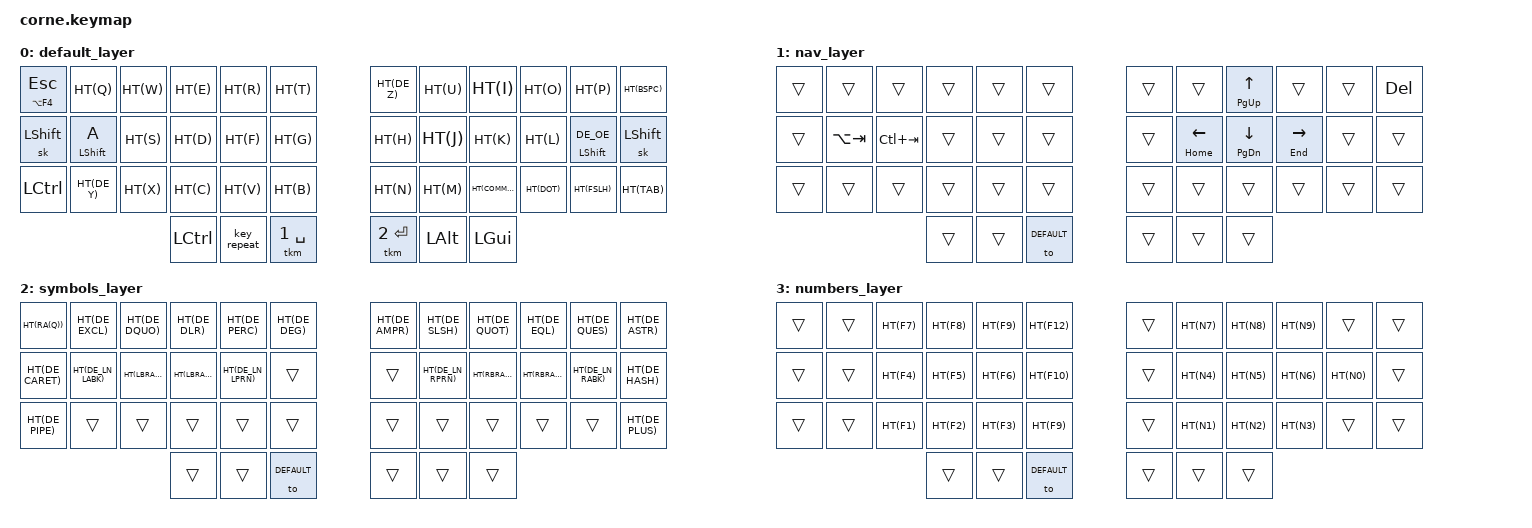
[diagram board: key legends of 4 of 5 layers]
/*
 * Copyright (c) 2020 The ZMK Contributors
 *
 * SPDX-License-Identifier: MIT
 */

#include <behaviors.dtsi>
#include <dt-bindings/zmk/keys.h>
#include <dt-bindings/zmk/bt.h>
#include <dt-bindings/zmk/outputs.h>
#include <dt-bindings/zmk/ext_power.h>
#include <dt-bindings/led/led.h>
#include <dt-bindings/zmk/backlight.h>
#include <dt-bindings/zmk/rgb.h>
#include <dt-bindings/zmk/reset.h>

#include "helper.h"
#include "symbols.h"
#include "keypos_42keys.h"

&led_strip {
    chain-length = <27>;
};

ZMK_BEHAVIOR(hrm, hold_tap,
    flavor = "balanced";
    tapping-term-ms = <280>;
    quick-tap-ms = <175>;
    bindings = <&kp>, <&kp>;
)

ZMK_BEHAVIOR(tkm, hold_tap,
    flavor = "balanced";
    tapping-term-ms = <280>;
    quick-tap-ms = <175>;
    bindings = <&mo>, <&kp>;
)

// Custom Combos
#undef COMBO_TERM
#define COMBO_TERM 50

#define DEFAULT 0
#define NAV 1
#define SYM 2
#define NUM 3
#define SYS 4

#define ______ &trans
#define HT(key) &hrm LC(key) key

ZMK_COMBO(sz,  &kp DE_SZ, LM3 RT0, ALL)
ZMK_COMBO(ue, &kp DE_UE, RT1 LT2, ALL)
ZMK_COMBO(ae, &kp DE_AE, LM4 LT2, ALL)
ZMK_COMBO(nav_layer, &to NAV, LM1 RM1, ALL)
ZMK_COMBO(sym_layer, &to SYM, LM2 RM2, ALL)
ZMK_COMBO(num_layer, &to NUM, LM3 RM3, ALL)
ZMK_COMBO(sys_layer_right, &mo 4, RH1 RH2, ALL)
ZMK_COMBO(sys_layer_left, &mo 4, LH1 LH2, ALL)

ZMK_LAYER(default_layer,
  // ╭─────────────┬─────────────┬─────────────┬─────────────┬─────────────┬─────────────╮   ╭─────────────┬─────────────┬─────────────┬─────────────┬─────────────┬─────────────╮
      &hrm LA(F4) ESC  HT(Q)       HT(W)         HT(E)         HT(R)         HT(T)             HT(DE_Z)      HT(U)         HT(I)         HT(O)         HT(P)         HT(BSPC)
  // ├─────────────┼─────────────┼─────────────┼─────────────┼─────────────┼─────────────┤   ├─────────────┼─────────────┼─────────────┼─────────────┼─────────────┼─────────────┤
      &sk LSHFT     &hrm LSHIFT A  HT(S)         HT(D)         HT(F)         HT(G)             HT(H)         HT(J)         HT(K)         HT(L)      &hrm LSHIFT DE_OE  &sk LSHFT
  // ├─────────────┼─────────────┼─────────────┼─────────────┼─────────────┼─────────────┤   ├─────────────┼─────────────┼─────────────┼─────────────┼─────────────┼─────────────┤
       &kp LCTRL     HT(DE_Y)      HT(X)         HT(C)         HT(V)         HT(B)             HT(N)         HT(M)         HT(COMMA)     HT(DOT)       HT(FSLH)      HT(TAB)
  // ╰─────────────┼─────────────┼─────────────┼─────────────┼─────────────┼─────────────┤   ├─────────────┼─────────────┼─────────────┼─────────────┼─────────────┼─────────────┤
                                                 &kp LCTRL     &key_repeat   &tkm 1 SPACE      &tkm 2 RET    &kp LALT      &kp LGUI
  //                                           ╰─────────────┴─────────────┴─────────────╯   ╰─────────────┴─────────────┴─────────────╯
)

ZMK_LAYER(nav_layer,
  // ╭─────────────┬─────────────┬─────────────┬─────────────┬─────────────┬─────────────╮   ╭─────────────┬─────────────┬─────────────┬─────────────┬─────────────┬─────────────╮
       ______       ______         ______        ______        ______        ______            ______        ______        &hrm PG_UP UP ______        ______        &kp DEL
  // ├─────────────┼─────────────┼─────────────┼─────────────┼─────────────┼─────────────┤   ├─────────────┼─────────────┼─────────────┼─────────────┼─────────────┼─────────────┤
       ______       &kp LA(TAB)    &kp LC(TAB)   ______        ______        ______            ______     &hrm HOME LEFT &hrm PG_DN DOWN &hrm END RIGHT  ______      ______
  // ├─────────────┼─────────────┼─────────────┼─────────────┼─────────────┼─────────────┤   ├─────────────┼─────────────┼─────────────┼─────────────┼─────────────┼─────────────┤
       ______        ______        ______        ______        ______        ______            ______        ______        ______        ______        ______        ______
  // ╰─────────────┼─────────────┼─────────────┼─────────────┼─────────────┼─────────────┤   ├─────────────┼─────────────┼─────────────┼─────────────┼─────────────┼─────────────┤
                                                 ______        ______        &to DEFAULT       ______        ______        ______
  //                                           ╰─────────────┴─────────────┴─────────────╯   ╰─────────────┴─────────────┴─────────────╯
)

ZMK_LAYER(symbols_layer,
  // ╭─────────────┬─────────────┬─────────────┬─────────────┬─────────────┬─────────────╮   ╭─────────────┬─────────────┬─────────────┬─────────────┬─────────────┬─────────────╮
       HT(RA(Q))     HT(DE_EXCL)   HT(DE_DQUO)   HT(DE_DLR)    HT(DE_PERC)   HT(DE_DEG)        HT(DE_AMPR)   HT(DE_SLSH)   HT(DE_QUOT)   HT(DE_EQL)    HT(DE_QUES)   HT(DE_ASTR)
  // ├─────────────┼─────────────┼─────────────┼─────────────┼─────────────┼─────────────┤   ├─────────────┼─────────────┼─────────────┼─────────────┼─────────────┼─────────────┤
       HT(DE_CARET) HT(DE_LN_LABK) HT(LBRACE)    HT(LBRACKET) HT(DE_LN_LPRN) ______             ______     HT(DE_LN_RPRN)  HT(RBRACKET)  HT(RBRACE)   HT(DE_LN_RABK) HT(DE_HASH)
  // ├─────────────┼─────────────┼─────────────┼─────────────┼─────────────┼─────────────┤   ├─────────────┼─────────────┼─────────────┼─────────────┼─────────────┼─────────────┤
       HT(DE_PIPE)   ______        ______        ______        ______        ______            ______        ______        ______        ______        ______        HT(DE_PLUS)
  // ╰─────────────┼─────────────┼─────────────┼─────────────┼─────────────┼─────────────┤   ├─────────────┼─────────────┼─────────────┼─────────────┼─────────────┼─────────────┤
                                                 ______        ______        &to DEFAULT       ______        ______        ______
  //                                           ╰─────────────┴─────────────┴─────────────╯   ╰─────────────┴─────────────┴─────────────╯
)

ZMK_LAYER(numbers_layer,
  // ╭─────────────┬─────────────┬─────────────┬─────────────┬─────────────┬─────────────╮   ╭─────────────┬─────────────┬─────────────┬─────────────┬─────────────┬─────────────╮
       ______        ______        HT(F7)        HT(F8)        HT(F9)        HT(F12)           ______        HT(N7)        HT(N8)        HT(N9)        ______        ______
  // ├─────────────┼─────────────┼─────────────┼─────────────┼─────────────┼─────────────┤   ├─────────────┼─────────────┼─────────────┼─────────────┼─────────────┼─────────────┤
       ______        ______        HT(F4)        HT(F5)        HT(F6)        HT(F10)           ______        HT(N4)        HT(N5)        HT(N6)        HT(N0)        ______
  // ├─────────────┼─────────────┼─────────────┼─────────────┼─────────────┼─────────────┤   ├─────────────┼─────────────┼─────────────┼─────────────┼─────────────┼─────────────┤
       ______        ______        HT(F1)        HT(F2)        HT(F3)        HT(F9)            ______        HT(N1)        HT(N2)        HT(N3)        ______        ______
  // ╰─────────────┼─────────────┼─────────────┼─────────────┼─────────────┼─────────────┤   ├─────────────┼─────────────┼─────────────┼─────────────┼─────────────┼─────────────┤
                                                 ______        ______        &to DEFAULT       ______         ______        ______
  //                                           ╰─────────────┴─────────────┴─────────────╯   ╰─────────────┴─────────────┴─────────────╯
)

ZMK_LAYER(system_layer,
  // ╭─────────────┬─────────────┬─────────────┬─────────────┬─────────────┬─────────────╮                              ╭─────────────┬─────────────┬─────────────┬─────────────┬─────────────┬─────────────╮
       &bootloader   &bt BT_CLR    &bt BT_NXT    ______        ______        ______                                       &ext_power EP_ON &ext_power EP_OFF        ______        ______        ______        &bootloader
  // ├─────────────┼─────────────┼─────────────┼─────────────┼─────────────┼─────────────┤                              ├─────────────┼─────────────┼─────────────┼─────────────┼─────────────┼─────────────┤
    &rgb_ug RGB_TOG &rgb_ug RGB_EFF &rgb_ug RGB_EFR &rgb_ug RGB_BRI &rgb_ug RGB_BRD &rgb_ug RGB_COLOR_HSB(128,100,100)    &bt BT_SEL 0  &bt BT_SEL 1  &bt BT_SEL 2  &bt BT_SEL 3  &bt BT_SEL 4  ______
  // ├─────────────┼─────────────┼─────────────┼─────────────┼─────────────┼─────────────┤                              ├─────────────┼─────────────┼─────────────┼─────────────┼─────────────┼─────────────┤
    &rgb_ug RGB_SPI &rgb_ug RGB_SPD &rgb_ug RGB_SAI &rgb_ug RGB_SAD &rgb_ug RGB_HUI &rgb_ug RGB_HUD                       ______        ______        ______        ______        ______        ______
  // ╰─────────────┼─────────────┼─────────────┼─────────────┼─────────────┼─────────────┤                              ├─────────────┼─────────────┼─────────────┼─────────────┼─────────────┼─────────────┤
                                                 ______        ______        ______                                       ______        ______        ______
  //                                           ╰─────────────┴─────────────┴─────────────╯                              ╰─────────────┴─────────────┴─────────────╯
)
